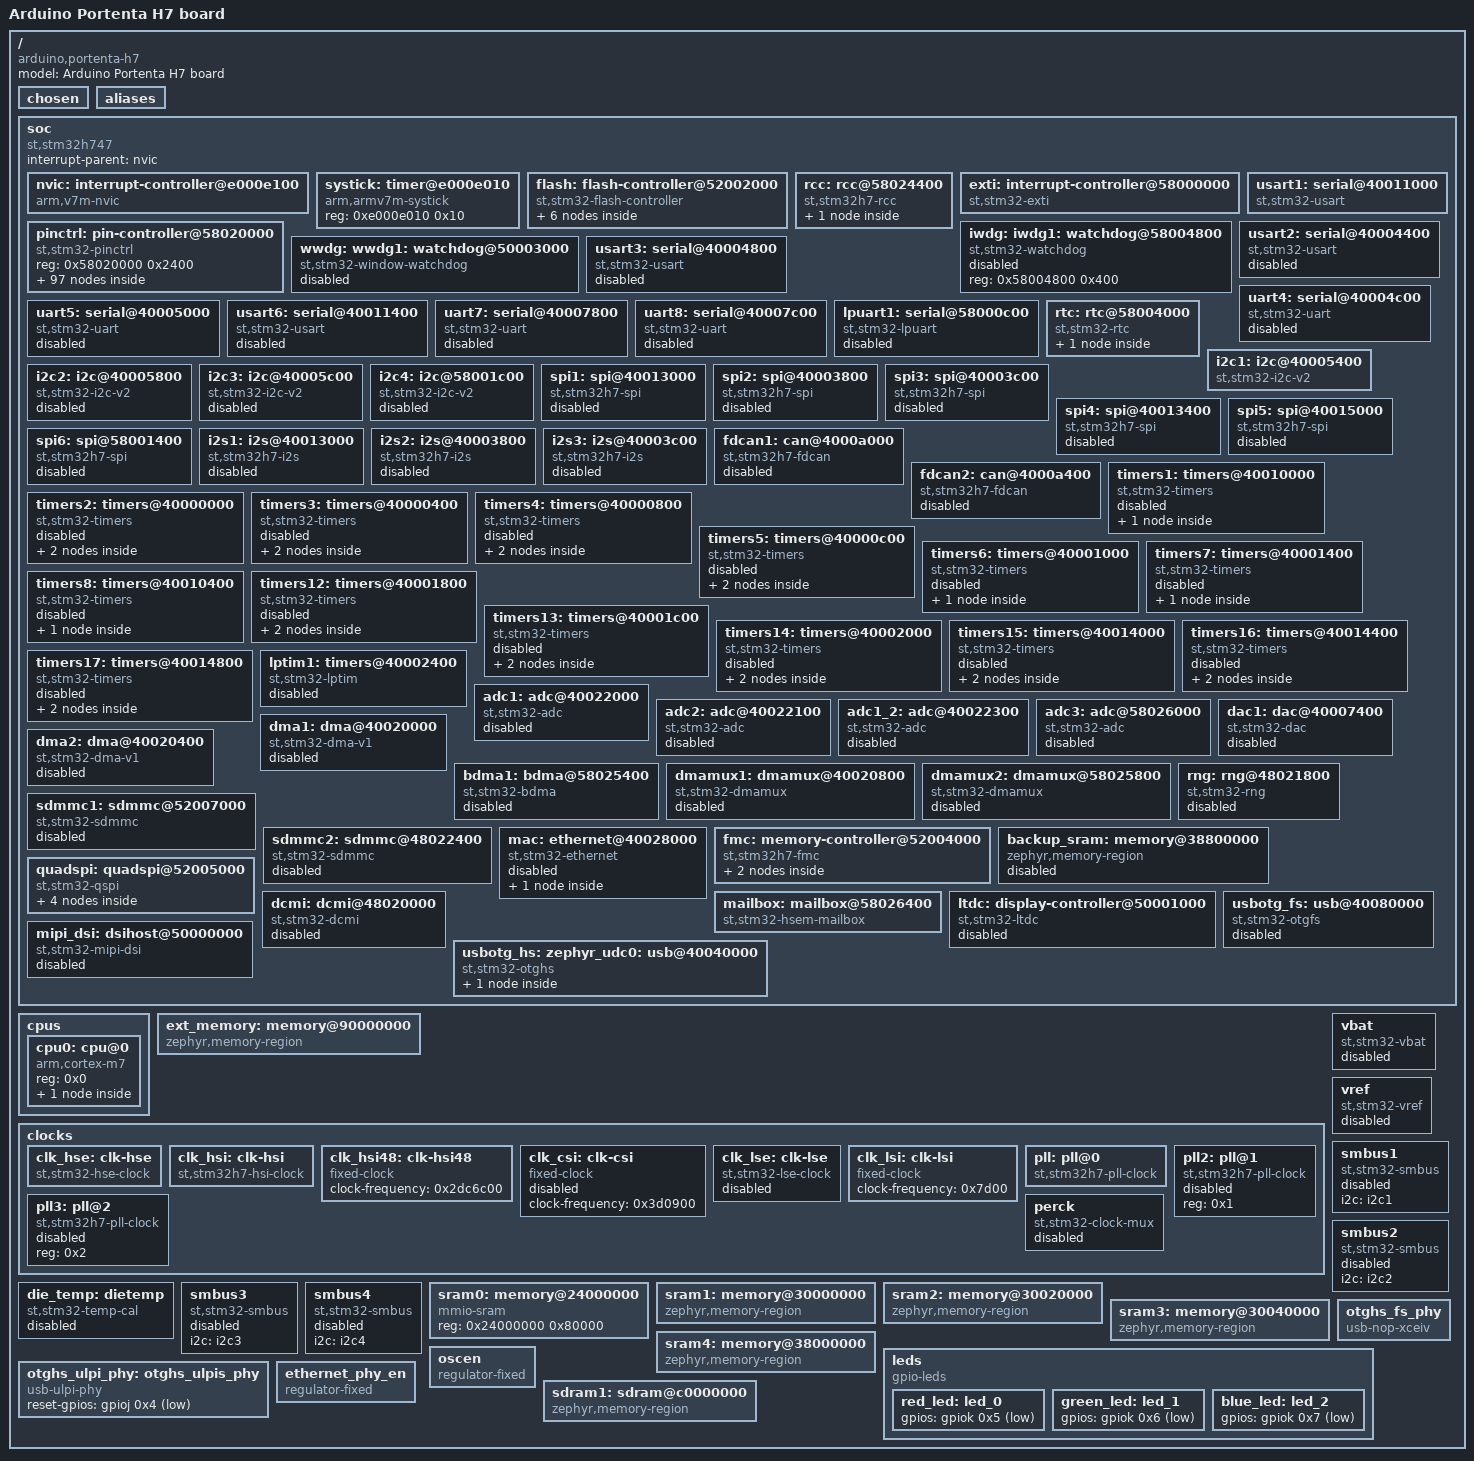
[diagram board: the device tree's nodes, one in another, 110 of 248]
/dts-v1/;

/ {
	#address-cells = < 0x1 >;
	#size-cells = < 0x1 >;
	model = "Arduino Portenta H7 board";
	compatible = "arduino,portenta-h7";
	chosen {
		zephyr,entropy = &rng;
		zephyr,flash-controller = &flash;
		zephyr,console = &cdc_acm_uart0;
		zephyr,shell-uart = &cdc_acm_uart0;
		zephyr,cdc-acm-uart0 = &cdc_acm_uart0;
		zephyr,sram = &sram0;
		zephyr,flash = &flash0;
		zephyr,code-partition = &slot0_partition;
	};
	aliases {
		led0 = &red_led;
		led1 = &green_led;
		led2 = &blue_led;
	};
	soc {
		#address-cells = < 0x1 >;
		#size-cells = < 0x1 >;
		compatible = "st,stm32h747", "st,stm32h7", "simple-bus";
		interrupt-parent = < &nvic >;
		ranges;
		nvic: interrupt-controller@e000e100 {
			#address-cells = < 0x1 >;
			compatible = "arm,v7m-nvic";
			reg = < 0xe000e100 0xc00 >;
			interrupt-controller;
			#interrupt-cells = < 0x2 >;
			arm,num-irq-priority-bits = < 0x4 >;
			phandle = < 0x1 >;
		};
		systick: timer@e000e010 {
			compatible = "arm,armv7m-systick";
			reg = < 0xe000e010 0x10 >;
		};
		flash: flash-controller@52002000 {
			compatible = "st,stm32-flash-controller", "st,stm32h7-flash-controller";
			reg = < 0x52002000 0x400 >;
			interrupts = < 0x4 0x0 >;
			clocks = < &rcc 0xd4 0x100 >;
			#address-cells = < 0x1 >;
			#size-cells = < 0x1 >;
			flash0: flash@8000000 {
				compatible = "st,stm32-nv-flash", "soc-nv-flash";
				write-block-size = < 0x20 >;
				erase-block-size = < 0x20000 >;
				max-erase-time = < 0xfa0 >;
				reg = < 0x8000000 0x100000 >;
				partitions {
					compatible = "fixed-partitions";
					#address-cells = < 0x1 >;
					#size-cells = < 0x1 >;
					boot_partition: partition@0 {
						label = "mcuboot";
						reg = < 0x0 0x10000 >;
						read-only;
					};
					scratch_partition: partition@10000 {
						label = "image-scratch";
						reg = < 0x10000 0x30000 >;
					};
					slot0_partition: partition@40000 {
						label = "image-0";
						reg = < 0x40000 0x60000 >;
					};
					slot1_partition: partition@A0000 {
						label = "image-1";
						reg = < 0xa0000 0x60000 >;
					};
				};
			};
		};
		rcc: rcc@58024400 {
			compatible = "st,stm32h7-rcc";
			#clock-cells = < 0x2 >;
			reg = < 0x58024400 0x400 >;
			d1cpre = < 0x1 >;
			hpre = < 0x2 >;
			d1ppre = < 0x2 >;
			d2ppre1 = < 0x2 >;
			d2ppre2 = < 0x2 >;
			d3ppre = < 0x2 >;
			clocks = < &pll >;
			clock-frequency = < 0x17d78400 >;
			phandle = < 0x2 >;
			rctl: reset-controller {
				compatible = "st,stm32-rcc-rctl";
				#reset-cells = < 0x1 >;
				phandle = < 0x4 >;
			};
		};
		exti: interrupt-controller@58000000 {
			compatible = "st,stm32-exti";
			interrupt-controller;
			#interrupt-cells = < 0x1 >;
			#address-cells = < 0x1 >;
			reg = < 0x58000000 0x400 >;
			num-lines = < 0x10 >;
			interrupts = < 0x6 0x0 >, < 0x7 0x0 >, < 0x8 0x0 >, < 0x9 0x0 >, < 0xa 0x0 >, < 0x17 0x0 >, < 0x28 0x0 >;
			interrupt-names = "line0", "line1", "line2", "line3", "line4", "line5-9", "line10-15";
			line-ranges = < 0x0 0x1 >, < 0x1 0x1 >, < 0x2 0x1 >, < 0x3 0x1 >, < 0x4 0x1 >, < 0x5 0x5 >, < 0xa 0x6 >;
		};
		pinctrl: pin-controller@58020000 {
			compatible = "st,stm32-pinctrl";
			#address-cells = < 0x1 >;
			#size-cells = < 0x1 >;
			reg = < 0x58020000 0x2400 >;
			gpioa: gpio@58020000 {
				compatible = "st,stm32-gpio";
				gpio-controller;
				#gpio-cells = < 0x2 >;
				reg = < 0x58020000 0x400 >;
				clocks = < &rcc 0xe0 0x1 >;
			};
			gpiob: gpio@58020400 {
				compatible = "st,stm32-gpio";
				gpio-controller;
				#gpio-cells = < 0x2 >;
				reg = < 0x58020400 0x400 >;
				clocks = < &rcc 0xe0 0x2 >;
			};
			gpioc: gpio@58020800 {
				compatible = "st,stm32-gpio";
				gpio-controller;
				#gpio-cells = < 0x2 >;
				reg = < 0x58020800 0x400 >;
				clocks = < &rcc 0xe0 0x4 >;
			};
			gpiod: gpio@58020C00 {
				compatible = "st,stm32-gpio";
				gpio-controller;
				#gpio-cells = < 0x2 >;
				reg = < 0x58020c00 0x400 >;
				clocks = < &rcc 0xe0 0x8 >;
			};
			gpioe: gpio@58021000 {
				compatible = "st,stm32-gpio";
				gpio-controller;
				#gpio-cells = < 0x2 >;
				reg = < 0x58021000 0x400 >;
				clocks = < &rcc 0xe0 0x10 >;
			};
			gpiof: gpio@58021400 {
				compatible = "st,stm32-gpio";
				gpio-controller;
				#gpio-cells = < 0x2 >;
				reg = < 0x58021400 0x400 >;
				clocks = < &rcc 0xe0 0x20 >;
			};
			gpiog: gpio@58021800 {
				compatible = "st,stm32-gpio";
				gpio-controller;
				#gpio-cells = < 0x2 >;
				reg = < 0x58021800 0x400 >;
				clocks = < &rcc 0xe0 0x40 >;
			};
			gpioh: gpio@58021C00 {
				compatible = "st,stm32-gpio";
				gpio-controller;
				#gpio-cells = < 0x2 >;
				reg = < 0x58021c00 0x400 >;
				clocks = < &rcc 0xe0 0x80 >;
				phandle = < 0x66 >;
			};
			gpioi: gpio@58022000 {
				compatible = "st,stm32-gpio";
				gpio-controller;
				#gpio-cells = < 0x2 >;
				reg = < 0x58022000 0x400 >;
				clocks = < &rcc 0xe0 0x100 >;
			};
			gpioj: gpio@58022400 {
				compatible = "st,stm32-gpio";
				gpio-controller;
				#gpio-cells = < 0x2 >;
				reg = < 0x58022400 0x400 >;
				clocks = < &rcc 0xe0 0x200 >;
				phandle = < 0x65 >;
			};
			gpiok: gpio@58022800 {
				compatible = "st,stm32-gpio";
				gpio-controller;
				#gpio-cells = < 0x2 >;
				reg = < 0x58022800 0x400 >;
				clocks = < &rcc 0xe0 0x400 >;
				phandle = < 0x64 >;
			};
			eth_crs_dv_pa7: eth_crs_dv_pa7 {
				pinmux = < 0xeb >;
				slew-rate = "very-high-speed";
				phandle = < 0x1c >;
			};
			eth_mdc_pc1: eth_mdc_pc1 {
				pinmux = < 0x42b >;
				slew-rate = "very-high-speed";
				phandle = < 0x1d >;
			};
			eth_mdio_pa2: eth_mdio_pa2 {
				pinmux = < 0x4b >;
				slew-rate = "very-high-speed";
				phandle = < 0x1b >;
			};
			eth_ref_clk_pa1: eth_ref_clk_pa1 {
				pinmux = < 0x2b >;
				slew-rate = "very-high-speed";
				phandle = < 0x1a >;
			};
			eth_rxd0_pc4: eth_rxd0_pc4 {
				pinmux = < 0x48b >;
				slew-rate = "very-high-speed";
				phandle = < 0x1e >;
			};
			eth_rxd1_pc5: eth_rxd1_pc5 {
				pinmux = < 0x4ab >;
				slew-rate = "very-high-speed";
				phandle = < 0x1f >;
			};
			eth_txd0_pg13: eth_txd0_pg13 {
				pinmux = < 0xdab >;
				slew-rate = "very-high-speed";
				phandle = < 0x22 >;
			};
			eth_txd1_pg12: eth_txd1_pg12 {
				pinmux = < 0xd8b >;
				slew-rate = "very-high-speed";
				phandle = < 0x21 >;
			};
			eth_tx_en_pg11: eth_tx_en_pg11 {
				pinmux = < 0xd6b >;
				slew-rate = "very-high-speed";
				phandle = < 0x20 >;
			};
			fdcan1_rx_pb8: fdcan1_rx_pb8 {
				pinmux = < 0x309 >;
				phandle = < 0x18 >;
			};
			fdcan1_tx_ph13: fdcan1_tx_ph13 {
				pinmux = < 0xfa9 >;
				phandle = < 0x19 >;
			};
			fmc_d2_pd0: fmc_d2_pd0 {
				pinmux = < 0x60c >;
				bias-pull-up;
				slew-rate = "very-high-speed";
				phandle = < 0x23 >;
			};
			fmc_d3_pd1: fmc_d3_pd1 {
				pinmux = < 0x62c >;
				bias-pull-up;
				slew-rate = "very-high-speed";
				phandle = < 0x24 >;
			};
			fmc_d13_pd8: fmc_d13_pd8 {
				pinmux = < 0x70c >;
				bias-pull-up;
				slew-rate = "very-high-speed";
				phandle = < 0x25 >;
			};
			fmc_d14_pd9: fmc_d14_pd9 {
				pinmux = < 0x72c >;
				bias-pull-up;
				slew-rate = "very-high-speed";
				phandle = < 0x26 >;
			};
			fmc_d15_pd10: fmc_d15_pd10 {
				pinmux = < 0x74c >;
				bias-pull-up;
				slew-rate = "very-high-speed";
				phandle = < 0x27 >;
			};
			fmc_d0_pd14: fmc_d0_pd14 {
				pinmux = < 0x7cc >;
				bias-pull-up;
				slew-rate = "very-high-speed";
				phandle = < 0x28 >;
			};
			fmc_d1_pd15: fmc_d1_pd15 {
				pinmux = < 0x7ec >;
				bias-pull-up;
				slew-rate = "very-high-speed";
				phandle = < 0x29 >;
			};
			fmc_nbl0_pe0: fmc_nbl0_pe0 {
				pinmux = < 0x80c >;
				bias-pull-up;
				slew-rate = "very-high-speed";
				phandle = < 0x2a >;
			};
			fmc_nbl1_pe1: fmc_nbl1_pe1 {
				pinmux = < 0x82c >;
				bias-pull-up;
				slew-rate = "very-high-speed";
				phandle = < 0x2b >;
			};
			fmc_d4_pe7: fmc_d4_pe7 {
				pinmux = < 0x8ec >;
				bias-pull-up;
				slew-rate = "very-high-speed";
				phandle = < 0x2c >;
			};
			fmc_d5_pe8: fmc_d5_pe8 {
				pinmux = < 0x90c >;
				bias-pull-up;
				slew-rate = "very-high-speed";
				phandle = < 0x2d >;
			};
			fmc_d6_pe9: fmc_d6_pe9 {
				pinmux = < 0x92c >;
				bias-pull-up;
				slew-rate = "very-high-speed";
				phandle = < 0x2e >;
			};
			fmc_d7_pe10: fmc_d7_pe10 {
				pinmux = < 0x94c >;
				bias-pull-up;
				slew-rate = "very-high-speed";
				phandle = < 0x2f >;
			};
			fmc_d8_pe11: fmc_d8_pe11 {
				pinmux = < 0x96c >;
				bias-pull-up;
				slew-rate = "very-high-speed";
				phandle = < 0x30 >;
			};
			fmc_d9_pe12: fmc_d9_pe12 {
				pinmux = < 0x98c >;
				bias-pull-up;
				slew-rate = "very-high-speed";
				phandle = < 0x31 >;
			};
			fmc_d10_pe13: fmc_d10_pe13 {
				pinmux = < 0x9ac >;
				bias-pull-up;
				slew-rate = "very-high-speed";
				phandle = < 0x32 >;
			};
			fmc_d11_pe14: fmc_d11_pe14 {
				pinmux = < 0x9cc >;
				bias-pull-up;
				slew-rate = "very-high-speed";
				phandle = < 0x33 >;
			};
			fmc_d12_pe15: fmc_d12_pe15 {
				pinmux = < 0x9ec >;
				bias-pull-up;
				slew-rate = "very-high-speed";
				phandle = < 0x34 >;
			};
			fmc_a0_pf0: fmc_a0_pf0 {
				pinmux = < 0xa0c >;
				bias-pull-up;
				slew-rate = "very-high-speed";
				phandle = < 0x35 >;
			};
			fmc_a1_pf1: fmc_a1_pf1 {
				pinmux = < 0xa2c >;
				bias-pull-up;
				slew-rate = "very-high-speed";
				phandle = < 0x36 >;
			};
			fmc_a2_pf2: fmc_a2_pf2 {
				pinmux = < 0xa4c >;
				bias-pull-up;
				slew-rate = "very-high-speed";
				phandle = < 0x37 >;
			};
			fmc_a3_pf3: fmc_a3_pf3 {
				pinmux = < 0xa6c >;
				bias-pull-up;
				slew-rate = "very-high-speed";
				phandle = < 0x38 >;
			};
			fmc_a4_pf4: fmc_a4_pf4 {
				pinmux = < 0xa8c >;
				bias-pull-up;
				slew-rate = "very-high-speed";
				phandle = < 0x39 >;
			};
			fmc_a5_pf5: fmc_a5_pf5 {
				pinmux = < 0xaac >;
				bias-pull-up;
				slew-rate = "very-high-speed";
				phandle = < 0x3a >;
			};
			fmc_sdnras_pf11: fmc_sdnras_pf11 {
				pinmux = < 0xb6c >;
				bias-pull-up;
				slew-rate = "very-high-speed";
				phandle = < 0x3b >;
			};
			fmc_a6_pf12: fmc_a6_pf12 {
				pinmux = < 0xb8c >;
				bias-pull-up;
				slew-rate = "very-high-speed";
				phandle = < 0x3c >;
			};
			fmc_a7_pf13: fmc_a7_pf13 {
				pinmux = < 0xbac >;
				bias-pull-up;
				slew-rate = "very-high-speed";
				phandle = < 0x3d >;
			};
			fmc_a8_pf14: fmc_a8_pf14 {
				pinmux = < 0xbcc >;
				bias-pull-up;
				slew-rate = "very-high-speed";
				phandle = < 0x3e >;
			};
			fmc_a9_pf15: fmc_a9_pf15 {
				pinmux = < 0xbec >;
				bias-pull-up;
				slew-rate = "very-high-speed";
				phandle = < 0x3f >;
			};
			fmc_a10_pg0: fmc_a10_pg0 {
				pinmux = < 0xc0c >;
				bias-pull-up;
				slew-rate = "very-high-speed";
				phandle = < 0x40 >;
			};
			fmc_a11_pg1: fmc_a11_pg1 {
				pinmux = < 0xc2c >;
				bias-pull-up;
				slew-rate = "very-high-speed";
				phandle = < 0x41 >;
			};
			fmc_a12_pg2: fmc_a12_pg2 {
				pinmux = < 0xc4c >;
				bias-pull-up;
				slew-rate = "very-high-speed";
				phandle = < 0x42 >;
			};
			fmc_a14_pg4: fmc_a14_pg4 {
				pinmux = < 0xc8c >;
				bias-pull-up;
				slew-rate = "very-high-speed";
				phandle = < 0x43 >;
			};
			fmc_a15_pg5: fmc_a15_pg5 {
				pinmux = < 0xcac >;
				bias-pull-up;
				slew-rate = "very-high-speed";
				phandle = < 0x44 >;
			};
			fmc_sdclk_pg8: fmc_sdclk_pg8 {
				pinmux = < 0xd0c >;
				bias-pull-up;
				slew-rate = "very-high-speed";
				phandle = < 0x45 >;
			};
			fmc_sdncas_pg15: fmc_sdncas_pg15 {
				pinmux = < 0xdec >;
				bias-pull-up;
				slew-rate = "very-high-speed";
				phandle = < 0x46 >;
			};
			fmc_sdcke0_ph2: fmc_sdcke0_ph2 {
				pinmux = < 0xe4c >;
				bias-pull-up;
				slew-rate = "very-high-speed";
				phandle = < 0x47 >;
			};
			fmc_sdne0_ph3: fmc_sdne0_ph3 {
				pinmux = < 0xe6c >;
				bias-pull-up;
				slew-rate = "very-high-speed";
				phandle = < 0x48 >;
			};
			fmc_sdnwe_ph5: fmc_sdnwe_ph5 {
				pinmux = < 0xeac >;
				bias-pull-up;
				slew-rate = "very-high-speed";
				phandle = < 0x49 >;
			};
			i2c1_scl_pb6: i2c1_scl_pb6 {
				pinmux = < 0x2c4 >;
				bias-pull-up;
				drive-open-drain;
				phandle = < 0xd >;
			};
			i2c3_scl_ph7: i2c3_scl_ph7 {
				pinmux = < 0xee4 >;
				bias-pull-up;
				drive-open-drain;
				phandle = < 0xf >;
			};
			i2c4_scl_ph11: i2c4_scl_ph11 {
				pinmux = < 0xf64 >;
				bias-pull-up;
				drive-open-drain;
				phandle = < 0x11 >;
			};
			i2c1_sda_pb7: i2c1_sda_pb7 {
				pinmux = < 0x2e4 >;
				bias-pull-up;
				drive-open-drain;
				phandle = < 0xe >;
			};
			i2c3_sda_ph8: i2c3_sda_ph8 {
				pinmux = < 0xf04 >;
				bias-pull-up;
				drive-open-drain;
				phandle = < 0x10 >;
			};
			i2c4_sda_ph12: i2c4_sda_ph12 {
				pinmux = < 0xf84 >;
				bias-pull-up;
				drive-open-drain;
				phandle = < 0x12 >;
			};
			quadspi_bk1_io0_pd11: quadspi_bk1_io0_pd11 {
				pinmux = < 0x769 >;
				slew-rate = "very-high-speed";
				phandle = < 0x4a >;
			};
			quadspi_bk1_io1_pd12: quadspi_bk1_io1_pd12 {
				pinmux = < 0x789 >;
				slew-rate = "very-high-speed";
				phandle = < 0x4b >;
			};
			quadspi_bk1_io3_pd13: quadspi_bk1_io3_pd13 {
				pinmux = < 0x7a9 >;
				slew-rate = "very-high-speed";
				phandle = < 0x4d >;
			};
			quadspi_bk1_io2_pf7: quadspi_bk1_io2_pf7 {
				pinmux = < 0xae9 >;
				slew-rate = "very-high-speed";
				phandle = < 0x4c >;
			};
			quadspi_clk_pf10: quadspi_clk_pf10 {
				pinmux = < 0xb49 >;
				slew-rate = "very-high-speed";
				phandle = < 0x4f >;
			};
			quadspi_bk1_ncs_pg6: quadspi_bk1_ncs_pg6 {
				pinmux = < 0xcca >;
				slew-rate = "very-high-speed";
				phandle = < 0x4e >;
			};
			spi2_miso_pc2: spi2_miso_pc2 {
				pinmux = < 0x445 >;
				bias-pull-down;
				phandle = < 0x15 >;
			};
			spi2_mosi_pc3: spi2_mosi_pc3 {
				pinmux = < 0x465 >;
				bias-pull-down;
				phandle = < 0x16 >;
			};
			spi2_nss_pi0: spi2_nss_pi0 {
				pinmux = < 0x1005 >;
				bias-pull-up;
				phandle = < 0x13 >;
			};
			spi2_sck_pi1: spi2_sck_pi1 {
				pinmux = < 0x1025 >;
				bias-pull-down;
				slew-rate = "very-high-speed";
				phandle = < 0x14 >;
			};
			usart1_rx_pa10: usart1_rx_pa10 {
				pinmux = < 0x147 >;
				phandle = < 0x6 >;
			};
			uart4_rx_pi9: uart4_rx_pi9 {
				pinmux = < 0x1128 >;
				phandle = < 0x8 >;
			};
			usart6_rx_pg9: usart6_rx_pg9 {
				pinmux = < 0xd27 >;
				phandle = < 0xa >;
			};
			uart8_rx_pj9: uart8_rx_pj9 {
				pinmux = < 0x1328 >;
				phandle = < 0xc >;
			};
			usart1_tx_pa9: usart1_tx_pa9 {
				pinmux = < 0x127 >;
				bias-pull-up;
				phandle = < 0x5 >;
			};
			uart4_tx_pa0: uart4_tx_pa0 {
				pinmux = < 0x8 >;
				bias-pull-up;
				phandle = < 0x7 >;
			};
			usart6_tx_pg14: usart6_tx_pg14 {
				pinmux = < 0xdc7 >;
				bias-pull-up;
				phandle = < 0x9 >;
			};
			uart8_tx_pj8: uart8_tx_pj8 {
				pinmux = < 0x1308 >;
				bias-pull-up;
				phandle = < 0xb >;
			};
			usb_otg_hs_ulpi_d0_pa3: usb_otg_hs_ulpi_d0_pa3 {
				pinmux = < 0x6a >;
				slew-rate = "high-speed";
				phandle = < 0x51 >;
			};
			usb_otg_hs_ulpi_ck_pa5: usb_otg_hs_ulpi_ck_pa5 {
				pinmux = < 0xaa >;
				slew-rate = "high-speed";
				phandle = < 0x52 >;
			};
			usb_otg_hs_ulpi_d1_pb0: usb_otg_hs_ulpi_d1_pb0 {
				pinmux = < 0x20a >;
				slew-rate = "high-speed";
				phandle = < 0x53 >;
			};
			usb_otg_hs_ulpi_d2_pb1: usb_otg_hs_ulpi_d2_pb1 {
				pinmux = < 0x22a >;
				slew-rate = "high-speed";
				phandle = < 0x54 >;
			};
			usb_otg_hs_ulpi_d7_pb5: usb_otg_hs_ulpi_d7_pb5 {
				pinmux = < 0x2aa >;
				slew-rate = "high-speed";
				phandle = < 0x55 >;
			};
			usb_otg_hs_ulpi_d3_pb10: usb_otg_hs_ulpi_d3_pb10 {
				pinmux = < 0x34a >;
				slew-rate = "high-speed";
				phandle = < 0x56 >;
			};
			usb_otg_hs_ulpi_d4_pb11: usb_otg_hs_ulpi_d4_pb11 {
				pinmux = < 0x36a >;
				slew-rate = "high-speed";
				phandle = < 0x57 >;
			};
			usb_otg_hs_ulpi_d5_pb12: usb_otg_hs_ulpi_d5_pb12 {
				pinmux = < 0x38a >;
				slew-rate = "high-speed";
				phandle = < 0x58 >;
			};
			usb_otg_hs_ulpi_d6_pb13: usb_otg_hs_ulpi_d6_pb13 {
				pinmux = < 0x3aa >;
				slew-rate = "high-speed";
				phandle = < 0x59 >;
			};
			usb_otg_hs_ulpi_stp_pc0: usb_otg_hs_ulpi_stp_pc0 {
				pinmux = < 0x40a >;
				slew-rate = "high-speed";
				phandle = < 0x5a >;
			};
			usb_otg_hs_ulpi_nxt_ph4: usb_otg_hs_ulpi_nxt_ph4 {
				pinmux = < 0xe8a >;
				slew-rate = "high-speed";
				phandle = < 0x5b >;
			};
			usb_otg_hs_ulpi_dir_pi11: usb_otg_hs_ulpi_dir_pi11 {
				pinmux = < 0x116a >;
				slew-rate = "high-speed";
				phandle = < 0x5c >;
			};
		};
		iwdg: iwdg1: watchdog@58004800 {
			compatible = "st,stm32-watchdog";
			reg = < 0x58004800 0x400 >;
			status = "disabled";
		};
		wwdg: wwdg1: watchdog@50003000 {
			compatible = "st,stm32-window-watchdog";
			reg = < 0x50003000 0x1000 >;
			clocks = < &rcc 0xe4 0x40 >;
			interrupts = < 0x0 0x7 >;
			status = "disabled";
		};
		usart1: serial@40011000 {
			compatible = "st,stm32-usart", "st,stm32-uart";
			reg = < 0x40011000 0x400 >;
			clocks = < &rcc 0xf0 0x10 >;
			resets = < &rctl 0x1304 >;
			interrupts = < 0x25 0x0 >;
			status = "okay";
			pinctrl-0 = < &usart1_tx_pa9 &usart1_rx_pa10 >;
			pinctrl-names = "default";
			current-speed = < 0x1c200 >;
		};
		usart2: serial@40004400 {
			compatible = "st,stm32-usart", "st,stm32-uart";
			reg = < 0x40004400 0x400 >;
			clocks = < &rcc 0xe8 0x20000 >;
			resets = < &rctl 0x1211 >;
			interrupts = < 0x26 0x0 >;
			status = "disabled";
		};
		usart3: serial@40004800 {
			compatible = "st,stm32-usart", "st,stm32-uart";
			reg = < 0x40004800 0x400 >;
			clocks = < &rcc 0xe8 0x40000 >;
			resets = < &rctl 0x1212 >;
			interrupts = < 0x27 0x0 >;
			status = "disabled";
		};
		uart4: serial@40004c00 {
			compatible = "st,stm32-uart";
			reg = < 0x40004c00 0x400 >;
			clocks = < &rcc 0xe8 0x80000 >;
			resets = < &rctl 0x1213 >;
			interrupts = < 0x34 0x0 >;
			status = "disabled";
			pinctrl-0 = < &uart4_tx_pa0 &uart4_rx_pi9 >;
			pinctrl-names = "default";
			current-speed = < 0x1c200 >;
		};
		uart5: serial@40005000 {
			compatible = "st,stm32-uart";
			reg = < 0x40005000 0x400 >;
			clocks = < &rcc 0xe8 0x100000 >;
			resets = < &rctl 0x1214 >;
			interrupts = < 0x35 0x0 >;
			status = "disabled";
		};
		usart6: serial@40011400 {
			compatible = "st,stm32-usart", "st,stm32-uart";
			reg = < 0x40011400 0x400 >;
			clocks = < &rcc 0xf0 0x20 >;
			resets = < &rctl 0x1305 >;
			interrupts = < 0x47 0x0 >;
			status = "disabled";
			pinctrl-0 = < &usart6_tx_pg14 &usart6_rx_pg9 >;
			pinctrl-names = "default";
			current-speed = < 0x1c200 >;
		};
		uart7: serial@40007800 {
			compatible = "st,stm32-uart";
			reg = < 0x40007800 0x400 >;
			clocks = < &rcc 0xe8 0x40000000 >;
			resets = < &rctl 0x121e >;
			interrupts = < 0x52 0x0 >;
			status = "disabled";
		};
		uart8: serial@40007c00 {
			compatible = "st,stm32-uart";
			reg = < 0x40007c00 0x400 >;
			clocks = < &rcc 0xe8 0x80000000 >;
			resets = < &rctl 0x121f >;
			interrupts = < 0x53 0x0 >;
			status = "disabled";
			pinctrl-0 = < &uart8_tx_pj8 &uart8_rx_pj9 >;
			pinctrl-names = "default";
			current-speed = < 0x1c200 >;
		};
		lpuart1: serial@58000c00 {
			compatible = "st,stm32-lpuart", "st,stm32-uart";
			reg = < 0x58000c00 0x400 >;
			clocks = < &rcc 0xf4 0x8 >;
			resets = < &rctl 0x1383 >;
			interrupts = < 0x8e 0x0 >;
			status = "disabled";
		};
		rtc: rtc@58004000 {
			compatible = "st,stm32-rtc";
			reg = < 0x58004000 0x400 >;
			interrupts = < 0x29 0x0 >;
			clocks = < &rcc 0xf4 0x10000 >;
			prescaler = < 0x8000 >;
			alarms-count = < 0x2 >;
			alrm-exti-line = < 0x11 >;
			status = "okay";
			bbram: backup_regs {
				compatible = "st,stm32-bbram";
				st,backup-regs = < 0x20 >;
				status = "disabled";
			};
		};
		i2c1: i2c@40005400 {
			compatible = "st,stm32-i2c-v2";
			clock-frequency = < 0x61a80 >;
			#address-cells = < 0x1 >;
			#size-cells = < 0x0 >;
			reg = < 0x40005400 0x400 >;
			clocks = < &rcc 0xe8 0x200000 >;
			interrupts = < 0x1f 0x0 >, < 0x20 0x0 >;
			interrupt-names = "event", "error";
			status = "okay";
			pinctrl-0 = < &i2c1_scl_pb6 &i2c1_sda_pb7 >;
			pinctrl-names = "default";
			phandle = < 0x60 >;
		};
		i2c2: i2c@40005800 {
			compatible = "st,stm32-i2c-v2";
			clock-frequency = < 0x186a0 >;
			#address-cells = < 0x1 >;
			#size-cells = < 0x0 >;
			reg = < 0x40005800 0x400 >;
			clocks = < &rcc 0xe8 0x400000 >;
			interrupts = < 0x21 0x0 >, < 0x22 0x0 >;
			interrupt-names = "event", "error";
			status = "disabled";
			phandle = < 0x61 >;
		};
		i2c3: i2c@40005c00 {
			compatible = "st,stm32-i2c-v2";
			clock-frequency = < 0x61a80 >;
			#address-cells = < 0x1 >;
			#size-cells = < 0x0 >;
			reg = < 0x40005c00 0x400 >;
			clocks = < &rcc 0xe8 0x800000 >;
			interrupts = < 0x48 0x0 >, < 0x49 0x0 >;
			interrupt-names = "event", "error";
			status = "disabled";
			pinctrl-0 = < &i2c3_scl_ph7 &i2c3_sda_ph8 >;
			pinctrl-names = "default";
			phandle = < 0x62 >;
		};
		i2c4: i2c@58001c00 {
			compatible = "st,stm32-i2c-v2";
			clock-frequency = < 0x61a80 >;
			#address-cells = < 0x1 >;
			#size-cells = < 0x0 >;
			reg = < 0x58001c00 0x400 >;
			clocks = < &rcc 0xf4 0x80 >;
			interrupts = < 0x5f 0x0 >, < 0x60 0x0 >;
			interrupt-names = "event", "error";
			status = "disabled";
			pinctrl-0 = < &i2c4_scl_ph11 &i2c4_sda_ph12 >;
			pinctrl-names = "default";
			phandle = < 0x63 >;
		};
		spi1: spi@40013000 {
			compatible = "st,stm32h7-spi", "st,stm32-spi-fifo", "st,stm32-spi";
			#address-cells = < 0x1 >;
			#size-cells = < 0x0 >;
			reg = < 0x40013000 0x400 >;
			clocks = < &rcc 0xf0 0x1000 >, < &rcc 0x9 0xec50 >;
			interrupts = < 0x23 0x0 >;
			status = "disabled";
		};
		spi2: spi@40003800 {
			compatible = "st,stm32h7-spi", "st,stm32-spi-fifo", "st,stm32-spi";
			#address-cells = < 0x1 >;
			#size-cells = < 0x0 >;
			reg = < 0x40003800 0x400 >;
			clocks = < &rcc 0xe8 0x4000 >, < &rcc 0x9 0xec50 >;
			interrupts = < 0x24 0x0 >;
			status = "disabled";
			pinctrl-0 = < &spi2_nss_pi0 &spi2_sck_pi1 &spi2_miso_pc2 &spi2_mosi_pc3 >;
			pinctrl-names = "default";
		};
		spi3: spi@40003c00 {
			compatible = "st,stm32h7-spi", "st,stm32-spi-fifo", "st,stm32-spi";
			#address-cells = < 0x1 >;
			#size-cells = < 0x0 >;
			reg = < 0x40003c00 0x400 >;
			clocks = < &rcc 0xe8 0x8000 >, < &rcc 0x9 0xec50 >;
			interrupts = < 0x33 0x0 >;
			status = "disabled";
		};
		spi4: spi@40013400 {
			compatible = "st,stm32h7-spi", "st,stm32-spi-fifo", "st,stm32-spi";
			#address-cells = < 0x1 >;
			#size-cells = < 0x0 >;
			reg = < 0x40013400 0x400 >;
			clocks = < &rcc 0xf0 0x2000 >;
			interrupts = < 0x54 0x0 >;
			status = "disabled";
		};
		spi5: spi@40015000 {
			compatible = "st,stm32h7-spi", "st,stm32-spi-fifo", "st,stm32-spi";
			#address-cells = < 0x1 >;
			#size-cells = < 0x0 >;
			reg = < 0x40015000 0x400 >;
			clocks = < &rcc 0xf0 0x100000 >;
			interrupts = < 0x55 0x0 >;
			status = "disabled";
		};
		spi6: spi@58001400 {
			compatible = "st,stm32h7-spi", "st,stm32-spi-fifo", "st,stm32-spi";
			#address-cells = < 0x1 >;
			#size-cells = < 0x0 >;
			reg = < 0x58001400 0x400 >;
			clocks = < &rcc 0xf4 0x20 >;
			interrupts = < 0x56 0x0 >;
			status = "disabled";
		};
		i2s1: i2s@40013000 {
			compatible = "st,stm32h7-i2s", "st,stm32-i2s";
			#address-cells = < 0x1 >;
			#size-cells = < 0x0 >;
			reg = < 0x40013000 0x400 >;
			clocks = < &rcc 0xf0 0x1000 >, < &rcc 0x9 0xec50 >;
			dmas = < &dmamux1 0x0 0x26 0x20440 &dmamux1 0x1 0x25 0x20480 >;
			dma-names = "tx", "rx";
			interrupts = < 0x23 0x3 >;
			status = "disabled";
		};
		i2s2: i2s@40003800 {
			compatible = "st,stm32h7-i2s", "st,stm32-i2s";
			#address-cells = < 0x1 >;
			#size-cells = < 0x0 >;
			reg = < 0x40003800 0x400 >;
			clocks = < &rcc 0xe8 0x4000 >, < &rcc 0x9 0xec50 >;
			dmas = < &dmamux1 0x0 0x28 0x20440 &dmamux1 0x1 0x27 0x20480 >;
			dma-names = "tx", "rx";
			interrupts = < 0x24 0x0 >;
			status = "disabled";
		};
		i2s3: i2s@40003c00 {
			compatible = "st,stm32h7-i2s", "st,stm32-i2s";
			#address-cells = < 0x1 >;
			#size-cells = < 0x0 >;
			reg = < 0x40003c00 0x400 >;
			clocks = < &rcc 0xe8 0x8000 >, < &rcc 0x9 0xec50 >;
			dmas = < &dmamux1 0x0 0x3e 0x20440 &dmamux1 0x1 0x3d 0x20480 >;
			dma-names = "tx", "rx";
			interrupts = < 0x33 0x0 >;
			status = "disabled";
		};
		fdcan1: can@4000a000 {
			compatible = "st,stm32h7-fdcan";
			reg = < 0x4000a000 0x400 >, < 0x4000ac00 0x350 >;
			reg-names = "m_can", "message_ram";
			clocks = < &rcc 0xec 0x100 >, < &rcc 0x9 0x17c50 >;
			interrupts = < 0x13 0x0 >, < 0x15 0x0 >, < 0x3f 0x0 >;
			interrupt-names = "int0", "int1", "calib";
			bosch,mram-cfg = < 0x0 0x1c 0x8 0x3 0x3 0x0 0x3 0x3 >;
			status = "disabled";
			pinctrl-0 = < &fdcan1_rx_pb8 &fdcan1_tx_ph13 >;
			pinctrl-names = "default";
		};
		fdcan2: can@4000a400 {
			compatible = "st,stm32h7-fdcan";
			reg = < 0x4000a400 0x400 >, < 0x4000ac00 0x6a0 >;
			reg-names = "m_can", "message_ram";
			clocks = < &rcc 0xec 0x100 >;
			interrupts = < 0x14 0x0 >, < 0x16 0x0 >, < 0x3f 0x0 >;
			interrupt-names = "int0", "int1", "calib";
			bosch,mram-cfg = < 0x350 0x1c 0x8 0x3 0x3 0x0 0x3 0x3 >;
			status = "disabled";
		};
		timers1: timers@40010000 {
			compatible = "st,stm32-timers";
			reg = < 0x40010000 0x400 >;
			clocks = < &rcc 0xf0 0x1 >;
			resets = < &rctl 0x1300 >;
			interrupts = < 0x18 0x0 >, < 0x19 0x0 >, < 0x1a 0x0 >, < 0x1b 0x0 >;
			interrupt-names = "brk", "up", "trgcom", "cc";
			st,prescaler = < 0x0 >;
			status = "disabled";
			pwm {
				compatible = "st,stm32-pwm";
				status = "disabled";
				#pwm-cells = < 0x3 >;
			};
		};
		timers2: timers@40000000 {
			compatible = "st,stm32-timers";
			reg = < 0x40000000 0x400 >;
			clocks = < &rcc 0xe8 0x1 >;
			resets = < &rctl 0x1200 >;
			interrupts = < 0x1c 0x0 >;
			interrupt-names = "global";
			st,prescaler = < 0x0 >;
			status = "disabled";
			pwm {
				compatible = "st,stm32-pwm";
				status = "disabled";
				#pwm-cells = < 0x3 >;
			};
			counter {
				compatible = "st,stm32-counter";
				status = "disabled";
			};
		};
		timers3: timers@40000400 {
			compatible = "st,stm32-timers";
			reg = < 0x40000400 0x400 >;
			clocks = < &rcc 0xe8 0x2 >;
			resets = < &rctl 0x1201 >;
			interrupts = < 0x1d 0x0 >;
			interrupt-names = "global";
			st,prescaler = < 0x0 >;
			status = "disabled";
			pwm {
				compatible = "st,stm32-pwm";
				status = "disabled";
				#pwm-cells = < 0x3 >;
			};
			counter {
				compatible = "st,stm32-counter";
				status = "disabled";
			};
		};
		timers4: timers@40000800 {
			compatible = "st,stm32-timers";
			reg = < 0x40000800 0x400 >;
			clocks = < &rcc 0xe8 0x4 >;
			resets = < &rctl 0x1202 >;
			interrupts = < 0x1e 0x0 >;
			interrupt-names = "global";
			st,prescaler = < 0x0 >;
			status = "disabled";
			pwm {
				compatible = "st,stm32-pwm";
				status = "disabled";
				#pwm-cells = < 0x3 >;
			};
			counter {
				compatible = "st,stm32-counter";
				status = "disabled";
			};
		};
		timers5: timers@40000c00 {
			compatible = "st,stm32-timers";
			reg = < 0x40000c00 0x400 >;
			clocks = < &rcc 0xe8 0x8 >;
			resets = < &rctl 0x1203 >;
			interrupts = < 0x32 0x0 >;
			interrupt-names = "global";
			st,prescaler = < 0x0 >;
			status = "disabled";
			pwm {
				compatible = "st,stm32-pwm";
				status = "disabled";
				#pwm-cells = < 0x3 >;
			};
			counter {
				compatible = "st,stm32-counter";
				status = "disabled";
			};
		};
		timers6: timers@40001000 {
			compatible = "st,stm32-timers";
			reg = < 0x40001000 0x400 >;
			clocks = < &rcc 0xe8 0x10 >;
			resets = < &rctl 0x1204 >;
			interrupts = < 0x36 0x0 >;
			interrupt-names = "global";
			st,prescaler = < 0x0 >;
			status = "disabled";
			counter {
				compatible = "st,stm32-counter";
				status = "disabled";
			};
		};
		timers7: timers@40001400 {
			compatible = "st,stm32-timers";
			reg = < 0x40001400 0x400 >;
			clocks = < &rcc 0xe8 0x20 >;
			resets = < &rctl 0x1205 >;
			interrupts = < 0x37 0x0 >;
			interrupt-names = "global";
			st,prescaler = < 0x0 >;
			status = "disabled";
			counter {
				compatible = "st,stm32-counter";
				status = "disabled";
			};
		};
		timers8: timers@40010400 {
			compatible = "st,stm32-timers";
			reg = < 0x40010400 0x400 >;
			clocks = < &rcc 0xf0 0x2 >;
			resets = < &rctl 0x1301 >;
			interrupts = < 0x2b 0x0 >, < 0x2c 0x0 >, < 0x2d 0x0 >, < 0x2e 0x0 >;
			interrupt-names = "brk", "up", "trgcom", "cc";
			st,prescaler = < 0x0 >;
			status = "disabled";
			pwm {
				compatible = "st,stm32-pwm";
				status = "disabled";
				#pwm-cells = < 0x3 >;
			};
		};
		timers12: timers@40001800 {
			compatible = "st,stm32-timers";
			reg = < 0x40001800 0x400 >;
			clocks = < &rcc 0xe8 0x40 >;
			resets = < &rctl 0x1206 >;
			interrupts = < 0x2b 0x0 >;
			interrupt-names = "global";
			st,prescaler = < 0x0 >;
			status = "disabled";
			pwm {
				compatible = "st,stm32-pwm";
				status = "disabled";
				#pwm-cells = < 0x3 >;
			};
			counter {
				compatible = "st,stm32-counter";
				status = "disabled";
			};
		};
		timers13: timers@40001c00 {
			compatible = "st,stm32-timers";
			reg = < 0x40001c00 0x400 >;
			clocks = < &rcc 0xe8 0x80 >;
			resets = < &rctl 0x1207 >;
			interrupts = < 0x2c 0x0 >;
			interrupt-names = "global";
			st,prescaler = < 0x0 >;
			status = "disabled";
			pwm {
				compatible = "st,stm32-pwm";
				status = "disabled";
				#pwm-cells = < 0x3 >;
			};
			counter {
				compatible = "st,stm32-counter";
				status = "disabled";
			};
		};
		timers14: timers@40002000 {
			compatible = "st,stm32-timers";
			reg = < 0x40002000 0x400 >;
			clocks = < &rcc 0xe8 0x100 >;
			resets = < &rctl 0x1208 >;
			interrupts = < 0x2d 0x0 >;
			interrupt-names = "global";
			st,prescaler = < 0x0 >;
			status = "disabled";
			pwm {
				compatible = "st,stm32-pwm";
				status = "disabled";
				#pwm-cells = < 0x3 >;
			};
			counter {
				compatible = "st,stm32-counter";
				status = "disabled";
			};
		};
		timers15: timers@40014000 {
			compatible = "st,stm32-timers";
			reg = < 0x40014000 0x400 >;
			clocks = < &rcc 0xf0 0x10000 >;
			resets = < &rctl 0x1310 >;
			interrupts = < 0x74 0x0 >;
			interrupt-names = "global";
			st,prescaler = < 0x0 >;
			status = "disabled";
			pwm {
				compatible = "st,stm32-pwm";
				status = "disabled";
				#pwm-cells = < 0x3 >;
			};
			counter {
				compatible = "st,stm32-counter";
				status = "disabled";
			};
		};
		timers16: timers@40014400 {
			compatible = "st,stm32-timers";
			reg = < 0x40014400 0x400 >;
			clocks = < &rcc 0xf0 0x20000 >;
			resets = < &rctl 0x1311 >;
			interrupts = < 0x75 0x0 >;
			interrupt-names = "global";
			st,prescaler = < 0x0 >;
			status = "disabled";
			pwm {
				compatible = "st,stm32-pwm";
				status = "disabled";
				#pwm-cells = < 0x3 >;
			};
			counter {
				compatible = "st,stm32-counter";
				status = "disabled";
			};
		};
		timers17: timers@40014800 {
			compatible = "st,stm32-timers";
			reg = < 0x40014800 0x400 >;
			clocks = < &rcc 0xf0 0x40000 >;
			resets = < &rctl 0x1312 >;
			interrupts = < 0x76 0x0 >;
			interrupt-names = "global";
			st,prescaler = < 0x0 >;
			status = "disabled";
			pwm {
				compatible = "st,stm32-pwm";
				status = "disabled";
				#pwm-cells = < 0x3 >;
			};
			counter {
				compatible = "st,stm32-counter";
				status = "disabled";
			};
		};
		lptim1: timers@40002400 {
			compatible = "st,stm32-lptim";
			clocks = < &rcc 0xe8 0x200 >;
			#address-cells = < 0x1 >;
			#size-cells = < 0x0 >;
			reg = < 0x40002400 0x400 >;
			interrupts = < 0x5d 0x1 >;
			interrupt-names = "wakeup";
			status = "disabled";
		};
		adc1: adc@40022000 {
			compatible = "st,stm32-adc";
			reg = < 0x40022000 0x400 >;
			clocks = < &rcc 0xd8 0x20 >;
			interrupts = < 0x12 0x0 >;
			status = "disabled";
			#io-channel-cells = < 0x1 >;
			resolutions = < 0x80e20c 0x75e20c 0x66e20c 0x53e20c 0x47e20c >;
			sampling-times = < 0x2 0x3 0x9 0x11 0x21 0x41 0x184 0x32b >;
			st,adc-sequencer = < 0x1 >;
		};
		adc2: adc@40022100 {
			compatible = "st,stm32-adc";
			reg = < 0x40022100 0x400 >;
			clocks = < &rcc 0xd8 0x20 >;
			interrupts = < 0x12 0x0 >;
			status = "disabled";
			#io-channel-cells = < 0x1 >;
			resolutions = < 0x80e20c 0x75e20c 0x66e20c 0x53e20c 0x47e20c >;
			sampling-times = < 0x2 0x3 0x9 0x11 0x21 0x41 0x184 0x32b >;
			st,adc-sequencer = < 0x1 >;
		};
		adc1_2: adc@40022300 {
			compatible = "st,stm32-adc";
			reg = < 0x40022300 0x400 >;
			clocks = < &rcc 0xd8 0x20 >;
			interrupts = < 0x12 0x0 >;
			status = "disabled";
			#io-channel-cells = < 0x1 >;
			resolutions = < 0x80e20c 0x75e20c 0x66e20c 0x53e20c 0x47e20c >;
			sampling-times = < 0x2 0x3 0x9 0x11 0x21 0x41 0x184 0x32b >;
			st,adc-sequencer = < 0x1 >;
		};
		adc3: adc@58026000 {
			compatible = "st,stm32-adc";
			reg = < 0x58026000 0x400 >;
			clocks = < &rcc 0xe0 0x1000000 >;
			interrupts = < 0x7f 0x0 >;
			status = "disabled";
			#io-channel-cells = < 0x1 >;
			resolutions = < 0x80e20c 0x75e20c 0x66e20c 0x53e20c 0x47e20c >;
			sampling-times = < 0x2 0x3 0x9 0x11 0x21 0x41 0x184 0x32b >;
			st,adc-sequencer = < 0x1 >;
			phandle = < 0x5f >;
		};
		dac1: dac@40007400 {
			compatible = "st,stm32-dac";
			reg = < 0x40007400 0x400 >;
			clocks = < &rcc 0xe8 0x20000000 >;
			status = "disabled";
			#io-channel-cells = < 0x1 >;
		};
		dma1: dma@40020000 {
			compatible = "st,stm32-dma-v1";
			#dma-cells = < 0x4 >;
			reg = < 0x40020000 0x400 >;
			interrupts = < 0xb 0x0 >, < 0xc 0x0 >, < 0xd 0x0 >, < 0xe 0x0 >, < 0xf 0x0 >, < 0x10 0x0 >, < 0x11 0x0 >, < 0x2f 0x0 >;
			clocks = < &rcc 0xd8 0x1 >;
			st,mem2mem;
			dma-offset = < 0x0 >;
			dma-requests = < 0x8 >;
			status = "disabled";
		};
		dma2: dma@40020400 {
			compatible = "st,stm32-dma-v1";
			#dma-cells = < 0x4 >;
			reg = < 0x40020400 0x400 >;
			interrupts = < 0x38 0x0 >, < 0x39 0x0 >, < 0x3a 0x0 >, < 0x3b 0x0 >, < 0x3c 0x0 >, < 0x44 0x0 >, < 0x45 0x0 >, < 0x46 0x0 >;
			clocks = < &rcc 0xd8 0x2 >;
			st,mem2mem;
			dma-offset = < 0x8 >;
			dma-requests = < 0x8 >;
			status = "disabled";
		};
		bdma1: bdma@58025400 {
			compatible = "st,stm32-bdma";
			#dma-cells = < 0x4 >;
			reg = < 0x58025400 0x400 >;
			interrupts = < 0x81 0x0 >, < 0x82 0x0 >, < 0x83 0x0 >, < 0x84 0x0 >, < 0x85 0x0 >, < 0x86 0x0 >, < 0x87 0x0 >, < 0x88 0x0 >;
			clocks = < &rcc 0xe0 0x200000 >;
			st,mem2mem;
			dma-offset = < 0x0 >;
			dma-requests = < 0x8 >;
			status = "disabled";
		};
		dmamux1: dmamux@40020800 {
			compatible = "st,stm32-dmamux";
			#dma-cells = < 0x3 >;
			reg = < 0x40020800 0x400 >;
			interrupts = < 0x66 0x0 >;
			clocks = < &rcc 0xd8 0x1 >;
			dma-channels = < 0x10 >;
			dma-generators = < 0x8 >;
			status = "disabled";
			dma-requests = < 0x6b >;
			phandle = < 0x17 >;
		};
		dmamux2: dmamux@58025800 {
			compatible = "st,stm32-dmamux";
			#dma-cells = < 0x3 >;
			reg = < 0x58025800 0x400 >;
			interrupts = < 0x80 0x0 >;
			clocks = < &rcc 0xe0 0x200000 >;
			dma-channels = < 0x8 >;
			dma-generators = < 0x8 >;
			status = "disabled";
			dma-requests = < 0x6b >;
		};
		rng: rng@48021800 {
			compatible = "st,stm32-rng";
			reg = < 0x48021800 0x400 >;
			clocks = < &rcc 0xdc 0x40 >;
			interrupts = < 0x50 0x0 >;
			status = "disabled";
		};
		sdmmc1: sdmmc@52007000 {
			compatible = "st,stm32-sdmmc";
			reg = < 0x52007000 0x400 >;
			clocks = < &rcc 0xd4 0x10000 >, < &rcc 0x9 0x304c >;
			resets = < &rctl 0xf90 >;
			interrupts = < 0x31 0x0 >;
			status = "disabled";
		};
		sdmmc2: sdmmc@48022400 {
			compatible = "st,stm32-sdmmc";
			reg = < 0x48022400 0x400 >;
			clocks = < &rcc 0xdc 0x200 >, < &rcc 0x9 0x304c >;
			resets = < &rctl 0x1089 >;
			interrupts = < 0x7c 0x0 >;
			status = "disabled";
		};
		mac: ethernet@40028000 {
			compatible = "st,stm32-ethernet";
			reg = < 0x40028000 0x8000 >;
			interrupts = < 0x3d 0x0 >;
			clock-names = "stmmaceth", "mac-clk-tx", "mac-clk-rx";
			clocks = < &rcc 0xd8 0x8000 >, < &rcc 0xd8 0x10000 >, < &rcc 0xd8 0x20000 >;
			status = "disabled";
			pinctrl-0 = < &eth_ref_clk_pa1 &eth_mdio_pa2 &eth_crs_dv_pa7 &eth_mdc_pc1 &eth_rxd0_pc4 &eth_rxd1_pc5 &eth_tx_en_pg11 &eth_txd1_pg12 &eth_txd0_pg13 >;
			pinctrl-names = "default";
			mdio: mdio {
				compatible = "st,stm32-mdio";
				#address-cells = < 0x1 >;
				#size-cells = < 0x0 >;
				status = "disabled";
			};
		};
		fmc: memory-controller@52004000 {
			compatible = "st,stm32h7-fmc";
			reg = < 0x52004000 0x400 >;
			clocks = < &rcc 0xd4 0x1000 >;
			status = "okay";
			pinctrl-0 = < &fmc_d2_pd0 &fmc_d3_pd1 &fmc_d13_pd8 &fmc_d14_pd9 &fmc_d15_pd10 &fmc_d0_pd14 &fmc_d1_pd15 &fmc_nbl0_pe0 &fmc_nbl1_pe1 &fmc_d4_pe7 &fmc_d5_pe8 &fmc_d6_pe9 &fmc_d7_pe10 &fmc_d8_pe11 &fmc_d9_pe12 &fmc_d10_pe13 &fmc_d11_pe14 &fmc_d12_pe15 &fmc_a0_pf0 &fmc_a1_pf1 &fmc_a2_pf2 &fmc_a3_pf3 &fmc_a4_pf4 &fmc_a5_pf5 &fmc_sdnras_pf11 &fmc_a6_pf12 &fmc_a7_pf13 &fmc_a8_pf14 &fmc_a9_pf15 &fmc_a10_pg0 &fmc_a11_pg1 &fmc_a12_pg2 &fmc_a14_pg4 &fmc_a15_pg5 &fmc_sdclk_pg8 &fmc_sdncas_pg15 &fmc_sdcke0_ph2 &fmc_sdne0_ph3 &fmc_sdnwe_ph5 >;
			pinctrl-names = "default";
			st,mem-swap = "disable";
			sdram: sdram {
				compatible = "st,stm32-fmc-sdram";
				#address-cells = < 0x1 >;
				#size-cells = < 0x0 >;
				status = "okay";
				mode-register = < 0x220 >;
				refresh-rate = < 0x2ab >;
				num-auto-refresh = < 0x8 >;
				bank@0 {
					reg = < 0x0 >;
					st,sdram-control = < 0x0 0x4 0x10 0x40 0x100 0x800 0x1000 0x0 >;
					st,sdram-timing = < 0x2 0x7 0x5 0x7 0x2 0x3 0x3 >;
				};
			};
		};
		backup_sram: memory@38800000 {
			compatible = "zephyr,memory-region", "st,stm32-backup-sram";
			reg = < 0x38800000 0x1000 >;
			clocks = < &rcc 0xe0 0x10000000 >;
			zephyr,memory-region = "BACKUP_SRAM";
			status = "disabled";
		};
		quadspi: quadspi@52005000 {
			compatible = "st,stm32-qspi";
			#address-cells = < 0x1 >;
			#size-cells = < 0x0 >;
			reg = < 0x52005000 0x34 >;
			interrupts = < 0x5c 0x0 >;
			clocks = < &rcc 0xd4 0x4000 >;
			status = "okay";
			pinctrl-0 = < &quadspi_bk1_io0_pd11 &quadspi_bk1_io1_pd12 &quadspi_bk1_io2_pf7 &quadspi_bk1_io3_pd13 &quadspi_bk1_ncs_pg6 &quadspi_clk_pf10 >;
			pinctrl-names = "default";
			mx25l12833f: qspi-nor-flash@90000000 {
				compatible = "st,stm32-qspi-nor";
				reg = < 0x90000000 0x1000000 >;
				qspi-max-frequency = < 0x2625a00 >;
				sfdp-bfp = [ E5 20 F1 FF FF FF FF 07 44 EB 08 6B 08 3B 04 BB FE FF FF FF FF FF 00 FF FF FF 44 EB 0C 20 0F 52 10 D8 00 FF 82 41 BD 00 81 E5 7B C6 44 03 67 38 30 B0 30 B0 F7 BD D5 5C 4A BE 29 FF E1 D0 FF FF ];
				jedec-id = [ 66 66 20 ];
				spi-bus-width = < 0x4 >;
				status = "okay";
				partitions {
					compatible = "fixed-partitions";
					#address-cells = < 0x1 >;
					#size-cells = < 0x1 >;
					storage_partition: partition@0 {
						label = "storage";
						reg = < 0x0 0xf80000 >;
					};
					wifi_firmware: partition@f80000 {
						label = "wifi-firmware";
						reg = < 0xf80000 0x80000 >;
					};
				};
			};
		};
		dcmi: dcmi@48020000 {
			compatible = "st,stm32-dcmi";
			reg = < 0x48020000 0x400 >;
			interrupts = < 0x4e 0x0 >;
			interrupt-names = "dcmi";
			clocks = < &rcc 0xdc 0x1 >;
			status = "disabled";
		};
		mailbox: mailbox@58026400 {
			compatible = "st,stm32-hsem-mailbox", "st,mbox-stm32-hsem";
			reg = < 0x58026400 0x400 >;
			clocks = < &rcc 0xe0 0x2000000 >;
			#mbox-cells = < 0x1 >;
			status = "okay";
			interrupts = < 0x7d 0x0 >;
		};
		ltdc: display-controller@50001000 {
			compatible = "st,stm32-ltdc";
			reg = < 0x50001000 0x200 >;
			interrupts = < 0x58 0x0 >, < 0x59 0x0 >;
			interrupt-names = "ltdc", "ltdc_er";
			clocks = < &rcc 0xe4 0x8 >;
			resets = < &rctl 0x1184 >;
			status = "disabled";
		};
		usbotg_hs: zephyr_udc0: usb@40040000 {
			compatible = "st,stm32-otghs";
			reg = < 0x40040000 0x40000 >;
			interrupts = < 0x4a 0x0 >, < 0x4b 0x0 >, < 0x4c 0x0 >, < 0x4d 0x0 >;
			interrupt-names = "ep1_out", "ep1_in", "wkup", "otghs";
			num-bidir-endpoints = < 0x4 >;
			ram-size = < 0x1000 >;
			maximum-speed = "high-speed";
			clocks = < &rcc 0xd8 0x6000000 >, < &rcc 0x5 0x37454 >;
			phys = < &otghs_ulpi_phy >;
			status = "okay";
			pinctrl-0 = < &usb_otg_hs_ulpi_d0_pa3 &usb_otg_hs_ulpi_ck_pa5 &usb_otg_hs_ulpi_d1_pb0 &usb_otg_hs_ulpi_d2_pb1 &usb_otg_hs_ulpi_d7_pb5 &usb_otg_hs_ulpi_d3_pb10 &usb_otg_hs_ulpi_d4_pb11 &usb_otg_hs_ulpi_d5_pb12 &usb_otg_hs_ulpi_d6_pb13 &usb_otg_hs_ulpi_stp_pc0 &usb_otg_hs_ulpi_nxt_ph4 &usb_otg_hs_ulpi_dir_pi11 >;
			pinctrl-names = "default";
			cdc_acm_uart0: cdc_acm_uart0 {
				compatible = "zephyr,cdc-acm-uart";
				status = "okay";
			};
		};
		usbotg_fs: usb@40080000 {
			compatible = "st,stm32-otgfs";
			reg = < 0x40080000 0x40000 >;
			interrupts = < 0x62 0x0 >, < 0x63 0x0 >, < 0x64 0x0 >, < 0x65 0x0 >;
			interrupt-names = "ep1_out", "ep1_in", "wkup", "otgfs";
			num-bidir-endpoints = < 0x9 >;
			ram-size = < 0x1000 >;
			maximum-speed = "full-speed";
			clocks = < &rcc 0xd8 0x8000000 >, < &rcc 0x5 0x37454 >;
			phys = < &otghs_fs_phy >;
			status = "disabled";
		};
		mipi_dsi: dsihost@50000000 {
			compatible = "st,stm32-mipi-dsi";
			#address-cells = < 0x1 >;
			#size-cells = < 0x0 >;
			reg = < 0x50000000 0x1000 >;
			clock-names = "dsiclk", "refclk", "pixelclk";
			clocks = < &rcc 0xe4 0x10 >, < &rcc 0x4 0xff >, < &rcc 0x10 0xff >;
			resets = < &rctl 0x1184 >;
			status = "disabled";
		};
	};
	cpus {
		#address-cells = < 0x1 >;
		#size-cells = < 0x0 >;
		cpu0: cpu@0 {
			device_type = "cpu";
			compatible = "arm,cortex-m7";
			reg = < 0x0 >;
			#address-cells = < 0x1 >;
			#size-cells = < 0x1 >;
			mpu: mpu@e000ed90 {
				compatible = "arm,armv7m-mpu";
				reg = < 0xe000ed90 0x40 >;
			};
		};
	};
	ext_memory: memory@90000000 {
		compatible = "zephyr,memory-region";
		reg = < 0x90000000 0x10000000 >;
		zephyr,memory-region = "EXTMEM";
		zephyr,memory-attr = < 0x2000000 >;
	};
	clocks {
		#address-cells = < 0x1 >;
		#size-cells = < 0x0 >;
		clk_hse: clk-hse {
			#clock-cells = < 0x0 >;
			compatible = "st,stm32-hse-clock";
			status = "okay";
			clock-frequency = < 0x17d7840 >;
			hse-bypass;
			phandle = < 0x5e >;
		};
		clk_hsi: clk-hsi {
			#clock-cells = < 0x0 >;
			compatible = "st,stm32h7-hsi-clock";
			clock-frequency = < 0x3d09000 >;
			status = "okay";
			hsi-div = < 0x1 >;
		};
		clk_hsi48: clk-hsi48 {
			#clock-cells = < 0x0 >;
			compatible = "fixed-clock";
			clock-frequency = < 0x2dc6c00 >;
			status = "okay";
		};
		clk_csi: clk-csi {
			#clock-cells = < 0x0 >;
			compatible = "fixed-clock";
			clock-frequency = < 0x3d0900 >;
			status = "disabled";
		};
		clk_lse: clk-lse {
			#clock-cells = < 0x0 >;
			compatible = "st,stm32-lse-clock";
			clock-frequency = < 0x8000 >;
			driving-capability = < 0x0 >;
			status = "disabled";
		};
		clk_lsi: clk-lsi {
			#clock-cells = < 0x0 >;
			compatible = "fixed-clock";
			clock-frequency = < 0x7d00 >;
			status = "okay";
		};
		pll: pll@0 {
			#clock-cells = < 0x0 >;
			compatible = "st,stm32h7-pll-clock";
			reg = < 0x0 >;
			status = "okay";
			div-m = < 0x5 >;
			mul-n = < 0xa0 >;
			div-p = < 0x2 >;
			div-q = < 0xa >;
			div-r = < 0x2 >;
			clocks = < &clk_hse >;
			phandle = < 0x3 >;
		};
		pll2: pll@1 {
			#clock-cells = < 0x0 >;
			compatible = "st,stm32h7-pll-clock";
			reg = < 0x1 >;
			status = "disabled";
		};
		pll3: pll@2 {
			#clock-cells = < 0x0 >;
			compatible = "st,stm32h7-pll-clock";
			reg = < 0x2 >;
			status = "disabled";
		};
		perck: perck {
			#clock-cells = < 0x0 >;
			compatible = "st,stm32-clock-mux";
			status = "disabled";
		};
	};
	die_temp: dietemp {
		compatible = "st,stm32-temp-cal";
		ts-cal1-addr = < 0x1ff1e820 >;
		ts-cal2-addr = < 0x1ff1e840 >;
		ts-cal1-temp = < 0x1e >;
		ts-cal2-temp = < 0x6e >;
		ts-cal-vrefanalog = < 0xce4 >;
		ts-cal-resolution = < 0x10 >;
		io-channels = < &adc3 0x12 >;
		status = "disabled";
	};
	vbat: vbat {
		compatible = "st,stm32-vbat";
		ratio = < 0x4 >;
		status = "disabled";
		io-channels = < &adc3 0x11 >;
	};
	vref: vref {
		compatible = "st,stm32-vref";
		vrefint-cal-addr = < 0x1ff1e860 >;
		vrefint-cal-mv = < 0xce4 >;
		status = "disabled";
		io-channels = < &adc3 0x13 >;
	};
	smbus1: smbus1 {
		compatible = "st,stm32-smbus";
		#address-cells = < 0x1 >;
		#size-cells = < 0x0 >;
		i2c = < &i2c1 >;
		status = "disabled";
	};
	smbus2: smbus2 {
		compatible = "st,stm32-smbus";
		#address-cells = < 0x1 >;
		#size-cells = < 0x0 >;
		i2c = < &i2c2 >;
		status = "disabled";
	};
	smbus3: smbus3 {
		compatible = "st,stm32-smbus";
		#address-cells = < 0x1 >;
		#size-cells = < 0x0 >;
		i2c = < &i2c3 >;
		status = "disabled";
	};
	smbus4: smbus4 {
		compatible = "st,stm32-smbus";
		#address-cells = < 0x1 >;
		#size-cells = < 0x0 >;
		i2c = < &i2c4 >;
		status = "disabled";
	};
	sram0: memory@24000000 {
		reg = < 0x24000000 0x80000 >;
		compatible = "mmio-sram";
	};
	sram1: memory@30000000 {
		reg = < 0x30000000 0x20000 >;
		compatible = "zephyr,memory-region", "mmio-sram";
		zephyr,memory-region = "SRAM1";
	};
	sram2: memory@30020000 {
		compatible = "zephyr,memory-region", "mmio-sram";
		reg = < 0x30020000 0x20000 >;
		zephyr,memory-region = "SRAM2";
	};
	sram3: memory@30040000 {
		compatible = "zephyr,memory-region", "mmio-sram";
		reg = < 0x30040000 0x8000 >;
		zephyr,memory-region = "SRAM3";
	};
	sram4: memory@38000000 {
		reg = < 0x38000000 0x10000 >;
		compatible = "zephyr,memory-region", "mmio-sram";
		zephyr,memory-region = "SRAM4";
	};
	otghs_fs_phy: otghs_fs_phy {
		compatible = "usb-nop-xceiv";
		#phy-cells = < 0x0 >;
		phandle = < 0x5d >;
	};
	leds {
		compatible = "gpio-leds";
		red_led: led_0 {
			gpios = < &gpiok 0x5 0x1 >;
		};
		green_led: led_1 {
			gpios = < &gpiok 0x6 0x1 >;
		};
		blue_led: led_2 {
			gpios = < &gpiok 0x7 0x1 >;
		};
	};
	otghs_ulpi_phy: otghs_ulpis_phy {
		compatible = "usb-ulpi-phy";
		reset-gpios = < &gpioj 0x4 0x1 >;
		#phy-cells = < 0x0 >;
		phandle = < 0x50 >;
	};
	oscen: oscen {
		compatible = "regulator-fixed";
		regulator-name = "oscen";
		enable-gpios = < &gpioh 0x1 0x0 >;
		regulator-boot-on;
		status = "okay";
	};
	ethernet_phy_en: ethernet_phy_en {
		compatible = "regulator-fixed";
		regulator-name = "ethernet-phy-reset-release";
		enable-gpios = < &gpioj 0xf 0x0 >;
		regulator-boot-on;
		status = "okay";
	};
	sdram1: sdram@c0000000 {
		compatible = "zephyr,memory-region", "mmio-sram";
		device_type = "memory";
		reg = < 0xc0000000 0x800000 >;
		zephyr,memory-region = "SDRAM1";
		zephyr,memory-attr = < 0x100000 >;
	};
};
